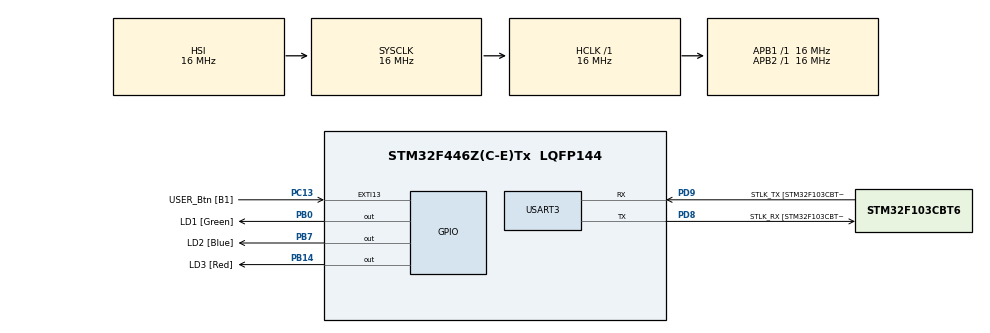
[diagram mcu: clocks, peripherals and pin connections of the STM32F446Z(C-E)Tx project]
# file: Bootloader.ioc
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Mcu.Family=STM32F4
Mcu.Name=STM32F446Z(C-E)Tx
Mcu.Package=LQFP144
NVIC.PriorityGroup=NVIC_PRIORITYGROUP_4
PB0.GPIO_Label=LD1 [Green]
PB0.Signal=GPIO_Output
PB14.GPIO_Label=LD3 [Red]
PB14.Signal=GPIO_Output
PB7.GPIO_Label=LD2 [Blue]
PB7.Signal=GPIO_Output
PC13.GPIO_Label=USER_Btn [B1]
PC13.Signal=GPXTI13
PD8.GPIO_Label=STLK_RX [STM32F103CBT6_PA3]
PD8.Mode=Asynchronous
PD8.Signal=USART3_TX
PD9.GPIO_Label=STLK_TX [STM32F103CBT6_PA2]
PD9.Mode=Asynchronous
PD9.Signal=USART3_RX
ProjectManager.HeapSize=0x200
ProjectManager.StackSize=0x400
ProjectManager.TargetToolchain=STM32CubeIDE
RCC.48MHZClocksFreq_Value=24000000
RCC.AHBFreq_Value=16000000
RCC.APB1Freq_Value=16000000
RCC.APB1TimFreq_Value=16000000
RCC.APB2Freq_Value=16000000
RCC.APB2TimFreq_Value=16000000
RCC.CortexFreq_Value=16000000
RCC.HCLKFreq_Value=16000000
RCC.HSE_VALUE=8000000
RCC.HSI_VALUE=16000000
RCC.PLLM=4
RCC.PLLMUL=RCC_PLL_MUL9
RCC.PLLN=168
RCC.PLLQ=7
RCC.PRESCALERUSB=RCC_USBCLKSOURCE_PLL_DIV1_5
RCC.SYSCLKFreq_VALUE=16000000
RCC.SYSCLKSourceVirtual=RCC_SYSCLKSOURCE_PLLCLK
RCC.USBFreq_Value=96000000
RCC.VCOOutputFreq_Value=672000000
USART3.VirtualMode=VM_ASYNC
board=NUCLEO-F446ZE

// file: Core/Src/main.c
/* USER CODE BEGIN Header */
/**
  ******************************************************************************
  * @file           : main.c
  * @brief          : Main program body
  ******************************************************************************
  * @attention
  *
  * Copyright (c) 2024 STMicroelectronics.
  * All rights reserved.
  *
  * This software is licensed under terms that can be found in the LICENSE file
  * in the root directory of this software component.
  * If no LICENSE file comes with this software, it is provided AS-IS.
  *
  ******************************************************************************
  */
/* USER CODE END Header */
#include "main.h"

/* USER CODE BEGIN Includes */
#include <stdio.h>
#include "bootloader.h"
#include "UART3_print.h"
/* USER CODE END Includes */

void SystemClock_Config(void);
static void MX_GPIO_Init(void);
//static void MX_USART3_UART_Init(void);

int main(void)
{

  /* MCU Configuration--------------------------------------------------------*/

  /* Reset of all peripherals, Initializes the Flash interface and the Systick. */
  HAL_Init();

  /* Configure the system clock */
  SystemClock_Config();

  /* Initialize all configured peripherals */
  MX_GPIO_Init();
  MX_USART3_UART_Init();
  /* USER CODE BEGIN 2 */
  printf("test \r\n");
  Bootloader_Init();
  /* USER CODE END 2 */

  /* Infinite loop */
  while (1)
  {

  }
}

void SystemClock_Config(void)
{
  RCC_OscInitTypeDef RCC_OscInitStruct = {0};
  RCC_ClkInitTypeDef RCC_ClkInitStruct = {0};

  /** Configure the main internal regulator output voltage
  */
  __HAL_RCC_PWR_CLK_ENABLE();
  __HAL_PWR_VOLTAGESCALING_CONFIG(PWR_REGULATOR_VOLTAGE_SCALE3);

  /** Initializes the RCC Oscillators according to the specified parameters
  * in the RCC_OscInitTypeDef structure.
  */
  RCC_OscInitStruct.OscillatorType = RCC_OSCILLATORTYPE_HSI;
  RCC_OscInitStruct.HSIState = RCC_HSI_ON;
  RCC_OscInitStruct.HSICalibrationValue = RCC_HSICALIBRATION_DEFAULT;
  RCC_OscInitStruct.PLL.PLLState = RCC_PLL_NONE;
  if (HAL_RCC_OscConfig(&RCC_OscInitStruct) != HAL_OK)
  {
    Error_Handler();
  }

  /** Initializes the CPU, AHB and APB buses clocks
  */
  RCC_ClkInitStruct.ClockType = RCC_CLOCKTYPE_HCLK|RCC_CLOCKTYPE_SYSCLK
                              |RCC_CLOCKTYPE_PCLK1|RCC_CLOCKTYPE_PCLK2;
  RCC_ClkInitStruct.SYSCLKSource = RCC_SYSCLKSOURCE_HSI;
  RCC_ClkInitStruct.AHBCLKDivider = RCC_SYSCLK_DIV1;
  RCC_ClkInitStruct.APB1CLKDivider = RCC_HCLK_DIV1;
  RCC_ClkInitStruct.APB2CLKDivider = RCC_HCLK_DIV1;

  if (HAL_RCC_ClockConfig(&RCC_ClkInitStruct, FLASH_LATENCY_0) != HAL_OK)
  {
    Error_Handler();
  }
}

static void MX_GPIO_Init(void)
{
  GPIO_InitTypeDef GPIO_InitStruct = {0};

  /* GPIO Ports Clock Enable */
  __HAL_RCC_GPIOC_CLK_ENABLE();
  __HAL_RCC_GPIOB_CLK_ENABLE();
  __HAL_RCC_GPIOD_CLK_ENABLE();

  /*Configure GPIO pin Output Level */
  HAL_GPIO_WritePin(GPIOB, LD1_Pin|LD3_Pin|LD2_Pin, GPIO_PIN_RESET);

  /*Configure GPIO pin : USER_Btn_Pin */
  GPIO_InitStruct.Pin = USER_Btn_Pin;
  GPIO_InitStruct.Mode = GPIO_MODE_IT_RISING;
  GPIO_InitStruct.Pull = GPIO_NOPULL;
  HAL_GPIO_Init(USER_Btn_GPIO_Port, &GPIO_InitStruct);

  /*Configure GPIO pins : LD1_Pin LD3_Pin LD2_Pin */
  GPIO_InitStruct.Pin = LD1_Pin|LD3_Pin|LD2_Pin;
  GPIO_InitStruct.Mode = GPIO_MODE_OUTPUT_PP;
  GPIO_InitStruct.Pull = GPIO_NOPULL;
  GPIO_InitStruct.Speed = GPIO_SPEED_FREQ_LOW;
  HAL_GPIO_Init(GPIOB, &GPIO_InitStruct);

}

void Error_Handler(void)
{
  __disable_irq();
  while (1)
  {
  }
}
